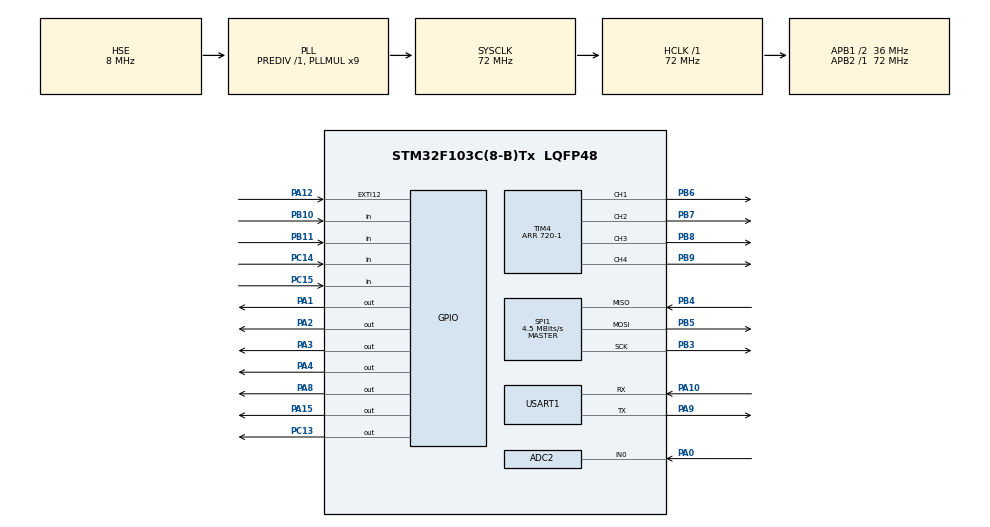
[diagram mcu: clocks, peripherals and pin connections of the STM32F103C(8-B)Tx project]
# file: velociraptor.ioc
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ADC2.Channel-4\#ChannelRegularConversion=ADC_CHANNEL_0
ADC2.NbrOfConversionFlag=1
ADC2.Rank-4\#ChannelRegularConversion=1
ADC2.SamplingTime-4\#ChannelRegularConversion=ADC_SAMPLETIME_1CYCLE_5
Dma.Request0=USART1_RX
Dma.Request1=USART1_TX
Dma.USART1_RX.0.Direction=DMA_PERIPH_TO_MEMORY
Dma.USART1_RX.0.Instance=DMA1_Channel5
Dma.USART1_RX.0.MemDataAlignment=DMA_MDATAALIGN_BYTE
Dma.USART1_RX.0.MemInc=DMA_MINC_ENABLE
Dma.USART1_RX.0.Mode=DMA_NORMAL
Dma.USART1_RX.0.PeriphDataAlignment=DMA_PDATAALIGN_BYTE
Dma.USART1_RX.0.PeriphInc=DMA_PINC_DISABLE
Dma.USART1_RX.0.Priority=DMA_PRIORITY_LOW
Dma.USART1_TX.1.Direction=DMA_MEMORY_TO_PERIPH
Dma.USART1_TX.1.Instance=DMA1_Channel4
Dma.USART1_TX.1.MemDataAlignment=DMA_MDATAALIGN_BYTE
Dma.USART1_TX.1.MemInc=DMA_MINC_ENABLE
Dma.USART1_TX.1.Mode=DMA_NORMAL
Dma.USART1_TX.1.PeriphDataAlignment=DMA_PDATAALIGN_BYTE
Dma.USART1_TX.1.PeriphInc=DMA_PINC_DISABLE
Dma.USART1_TX.1.Priority=DMA_PRIORITY_LOW
Mcu.Family=STM32F1
Mcu.Name=STM32F103C(8-B)Tx
Mcu.Package=LQFP48
NVIC.DMA1_Channel4_IRQn=true\:0\:0\:false\:false\:true\:false\:true\:true
NVIC.DMA1_Channel5_IRQn=true\:0\:0\:false\:false\:true\:false\:true\:true
NVIC.EXTI15_10_IRQn=true\:0\:0\:false\:false\:true\:true\:true\:true
NVIC.PriorityGroup=NVIC_PRIORITYGROUP_4
NVIC.TIM2_IRQn=true\:0\:0\:false\:false\:true\:true\:true\:true
NVIC.USART1_IRQn=true\:0\:0\:false\:false\:true\:true\:true\:true
PA0-WKUP.Signal=ADCx_IN0
PA1.Signal=GPIO_Output
PA10.Mode=Asynchronous
PA10.Signal=USART1_RX
PA12.GPIO_ModeDefaultEXTI=GPIO_MODE_IT_RISING
PA12.Signal=GPXTI12
PA13.Mode=Serial_Wire
PA13.Signal=SYS_JTMS-SWDIO
PA14.Mode=Serial_Wire
PA14.Signal=SYS_JTCK-SWCLK
PA15.GPIO_Speed=GPIO_SPEED_FREQ_HIGH
PA15.Signal=GPIO_Output
PA2.Signal=GPIO_Output
PA3.Signal=GPIO_Output
PA4.Signal=GPIO_Output
PA8.Signal=GPIO_Output
PA9.Mode=Asynchronous
PA9.Signal=USART1_TX
PB10.GPIO_PuPd=GPIO_PULLUP
PB10.Signal=GPIO_Input
PB11.GPIO_PuPd=GPIO_PULLUP
PB11.Signal=GPIO_Input
PB3.Mode=Full_Duplex_Master
PB3.Signal=SPI1_SCK
PB4.Mode=Full_Duplex_Master
PB4.Signal=SPI1_MISO
PB5.Mode=Full_Duplex_Master
PB5.Signal=SPI1_MOSI
PB6.Signal=S_TIM4_CH1
PB7.Signal=S_TIM4_CH2
PB8.Signal=S_TIM4_CH3
PB9.Signal=S_TIM4_CH4
PC13-TAMPER-RTC.Signal=GPIO_Output
PC14-OSC32_IN.GPIO_PuPd=GPIO_PULLUP
PC14-OSC32_IN.Signal=GPIO_Input
PC15-OSC32_OUT.GPIO_PuPd=GPIO_PULLUP
PC15-OSC32_OUT.Signal=GPIO_Input
PD0-OSC_IN.Mode=HSE-External-Oscillator
PD0-OSC_IN.Signal=RCC_OSC_IN
PD1-OSC_OUT.Mode=HSE-External-Oscillator
PD1-OSC_OUT.Signal=RCC_OSC_OUT
ProjectManager.HeapSize=0x200
ProjectManager.StackSize=0x400
ProjectManager.TargetToolchain=STM32CubeIDE
RCC.ADCPresc=RCC_ADCPCLK2_DIV6
RCC.AHBFreq_Value=72000000
RCC.APB1CLKDivider=RCC_HCLK_DIV2
RCC.APB1Freq_Value=36000000
RCC.APB1TimFreq_Value=72000000
RCC.APB2Freq_Value=72000000
RCC.APB2TimFreq_Value=72000000
RCC.HCLKFreq_Value=72000000
RCC.PLLMUL=RCC_PLL_MUL9
RCC.PLLSourceVirtual=RCC_PLLSOURCE_HSE
RCC.SYSCLKFreq_VALUE=72000000
RCC.SYSCLKSource=RCC_SYSCLKSOURCE_PLLCLK
RCC.USBFreq_Value=72000000
SH.ADCx_IN0.0=ADC2_IN0,IN0
SH.S_TIM4_CH1.0=TIM4_CH1,PWM Generation1 CH1
SH.S_TIM4_CH2.0=TIM4_CH2,PWM Generation2 CH2
SH.S_TIM4_CH3.0=TIM4_CH3,PWM Generation3 CH3
SH.S_TIM4_CH4.0=TIM4_CH4,PWM Generation4 CH4
SPI1.BaudRatePrescaler=SPI_BAUDRATEPRESCALER_16
SPI1.CLKPhase=SPI_PHASE_2EDGE
SPI1.CLKPolarity=SPI_POLARITY_HIGH
SPI1.CalculateBaudRate=4.5 MBits/s
SPI1.Direction=SPI_DIRECTION_2LINES
SPI1.Mode=SPI_MODE_MASTER
SPI1.VirtualType=VM_MASTER
TIM2.AutoReloadPreload=TIM_AUTORELOAD_PRELOAD_ENABLE
TIM2.Period=10-1
TIM2.Prescaler=720-1
TIM3.Period=1080-1
TIM3.TIM_MasterOutputTrigger=TIM_TRGO_UPDATE
TIM4.AutoReloadPreload=TIM_AUTORELOAD_PRELOAD_ENABLE
TIM4.Channel-PWM\ Generation1\ CH1=TIM_CHANNEL_1
TIM4.Channel-PWM\ Generation2\ CH2=TIM_CHANNEL_2
TIM4.Channel-PWM\ Generation3\ CH3=TIM_CHANNEL_3
TIM4.Channel-PWM\ Generation4\ CH4=TIM_CHANNEL_4
TIM4.ClockDivision=TIM_CLOCKDIVISION_DIV1
TIM4.Period=720-1
USART1.VirtualMode=VM_ASYNC
VP_TIM2_VS_ClockSourceINT.Mode=Internal
VP_TIM3_VS_ClockSourceINT.Mode=Internal
VP_TIM4_VS_ClockSourceINT.Mode=Internal
board=custom

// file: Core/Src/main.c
/* USER CODE BEGIN Header */
/**
  ******************************************************************************
  * @file           : main.c
  * @brief          : Main program body
  ******************************************************************************
  * @attention
  *
  * Copyright (c) 2024 STMicroelectronics.
  * All rights reserved.
  *
  * This software is licensed under terms that can be found in the LICENSE file
  * in the root directory of this software component.
  * If no LICENSE file comes with this software, it is provided AS-IS.
  *
  ******************************************************************************
  */
/* USER CODE END Header */
#include "main.h"

/* USER CODE BEGIN Includes */
#include "velociraptor3.h"
#include "velociraptor3_comms.h"
/* USER CODE END Includes */

ADC_HandleTypeDef hadc2;

SPI_HandleTypeDef hspi1;

TIM_HandleTypeDef htim2;
TIM_HandleTypeDef htim3;
TIM_HandleTypeDef htim4;

UART_HandleTypeDef huart1;
DMA_HandleTypeDef hdma_usart1_rx;
DMA_HandleTypeDef hdma_usart1_tx;

void SystemClock_Config(void);
static void MX_GPIO_Init(void);
static void MX_DMA_Init(void);
static void MX_TIM4_Init(void);
static void MX_USART1_UART_Init(void);
static void MX_TIM3_Init(void);
static void MX_ADC2_Init(void);
static void MX_TIM2_Init(void);
static void MX_SPI1_Init(void);

int main(void)
{

  /* MCU Configuration--------------------------------------------------------*/

  /* Reset of all peripherals, Initializes the Flash interface and the Systick. */
   HAL_Init();

  /* Configure the system clock */
  SystemClock_Config();

  /* Initialize all configured peripherals */
  MX_GPIO_Init();
  MX_DMA_Init();
  MX_TIM4_Init();
  MX_USART1_UART_Init();
  MX_TIM3_Init();
  MX_ADC2_Init();
  MX_TIM2_Init();
  MX_SPI1_Init();
  /* USER CODE BEGIN 2 */
  velociraptor3_init();
  //velociraptor2_comms_init();
  /* USER CODE END 2 */

  /* Infinite loop */
  /* USER CODE BEGIN WHILE */
  while (1)
  {
	velociraptor3_main_loop();
    /* USER CODE END WHILE */

  }
}

void SystemClock_Config(void)
{
  RCC_OscInitTypeDef RCC_OscInitStruct = {0};
  RCC_ClkInitTypeDef RCC_ClkInitStruct = {0};
  RCC_PeriphCLKInitTypeDef PeriphClkInit = {0};

  /** Initializes the RCC Oscillators according to the specified parameters
  * in the RCC_OscInitTypeDef structure.
  */
  RCC_OscInitStruct.OscillatorType = RCC_OSCILLATORTYPE_HSE;
  RCC_OscInitStruct.HSEState = RCC_HSE_ON;
  RCC_OscInitStruct.HSEPredivValue = RCC_HSE_PREDIV_DIV1;
  RCC_OscInitStruct.HSIState = RCC_HSI_ON;
  RCC_OscInitStruct.PLL.PLLState = RCC_PLL_ON;
  RCC_OscInitStruct.PLL.PLLSource = RCC_PLLSOURCE_HSE;
  RCC_OscInitStruct.PLL.PLLMUL = RCC_PLL_MUL9;
  if (HAL_RCC_OscConfig(&RCC_OscInitStruct) != HAL_OK)
  {
    Error_Handler();
  }

  /** Initializes the CPU, AHB and APB buses clocks
  */
  RCC_ClkInitStruct.ClockType = RCC_CLOCKTYPE_HCLK|RCC_CLOCKTYPE_SYSCLK
                              |RCC_CLOCKTYPE_PCLK1|RCC_CLOCKTYPE_PCLK2;
  RCC_ClkInitStruct.SYSCLKSource = RCC_SYSCLKSOURCE_PLLCLK;
  RCC_ClkInitStruct.AHBCLKDivider = RCC_SYSCLK_DIV1;
  RCC_ClkInitStruct.APB1CLKDivider = RCC_HCLK_DIV2;
  RCC_ClkInitStruct.APB2CLKDivider = RCC_HCLK_DIV1;

  if (HAL_RCC_ClockConfig(&RCC_ClkInitStruct, FLASH_LATENCY_2) != HAL_OK)
  {
    Error_Handler();
  }
  PeriphClkInit.PeriphClockSelection = RCC_PERIPHCLK_ADC;
  PeriphClkInit.AdcClockSelection = RCC_ADCPCLK2_DIV6;
  if (HAL_RCCEx_PeriphCLKConfig(&PeriphClkInit) != HAL_OK)
  {
    Error_Handler();
  }
}

static void MX_ADC2_Init(void)
{

  ADC_ChannelConfTypeDef sConfig = {0};

  /** Common config
  */
  hadc2.Instance = ADC2;
  hadc2.Init.ScanConvMode = ADC_SCAN_DISABLE;
  hadc2.Init.ContinuousConvMode = DISABLE;
  hadc2.Init.DiscontinuousConvMode = DISABLE;
  hadc2.Init.ExternalTrigConv = ADC_SOFTWARE_START;
  hadc2.Init.DataAlign = ADC_DATAALIGN_RIGHT;
  hadc2.Init.NbrOfConversion = 1;
  if (HAL_ADC_Init(&hadc2) != HAL_OK)
  {
    Error_Handler();
  }

  /** Configure Regular Channel
  */
  sConfig.Channel = ADC_CHANNEL_0;
  sConfig.Rank = ADC_REGULAR_RANK_1;
  sConfig.SamplingTime = ADC_SAMPLETIME_1CYCLE_5;
  if (HAL_ADC_ConfigChannel(&hadc2, &sConfig) != HAL_OK)
  {
    Error_Handler();
  }

}

static void MX_SPI1_Init(void)
{

  /* SPI1 parameter configuration*/
  hspi1.Instance = SPI1;
  hspi1.Init.Mode = SPI_MODE_MASTER;
  hspi1.Init.Direction = SPI_DIRECTION_2LINES;
  hspi1.Init.DataSize = SPI_DATASIZE_8BIT;
  hspi1.Init.CLKPolarity = SPI_POLARITY_HIGH;
  hspi1.Init.CLKPhase = SPI_PHASE_2EDGE;
  hspi1.Init.NSS = SPI_NSS_SOFT;
  hspi1.Init.BaudRatePrescaler = SPI_BAUDRATEPRESCALER_16;
  hspi1.Init.FirstBit = SPI_FIRSTBIT_MSB;
  hspi1.Init.TIMode = SPI_TIMODE_DISABLE;
  hspi1.Init.CRCCalculation = SPI_CRCCALCULATION_DISABLE;
  hspi1.Init.CRCPolynomial = 10;
  if (HAL_SPI_Init(&hspi1) != HAL_OK)
  {
    Error_Handler();
  }

}

static void MX_TIM2_Init(void)
{

  TIM_ClockConfigTypeDef sClockSourceConfig = {0};
  TIM_MasterConfigTypeDef sMasterConfig = {0};

  htim2.Instance = TIM2;
  htim2.Init.Prescaler = 720-1;
  htim2.Init.CounterMode = TIM_COUNTERMODE_UP;
  htim2.Init.Period = 10-1;
  htim2.Init.ClockDivision = TIM_CLOCKDIVISION_DIV1;
  htim2.Init.AutoReloadPreload = TIM_AUTORELOAD_PRELOAD_ENABLE;
  if (HAL_TIM_Base_Init(&htim2) != HAL_OK)
  {
    Error_Handler();
  }
  sClockSourceConfig.ClockSource = TIM_CLOCKSOURCE_INTERNAL;
  if (HAL_TIM_ConfigClockSource(&htim2, &sClockSourceConfig) != HAL_OK)
  {
    Error_Handler();
  }
  sMasterConfig.MasterOutputTrigger = TIM_TRGO_RESET;
  sMasterConfig.MasterSlaveMode = TIM_MASTERSLAVEMODE_DISABLE;
  if (HAL_TIMEx_MasterConfigSynchronization(&htim2, &sMasterConfig) != HAL_OK)
  {
    Error_Handler();
  }

}

static void MX_TIM3_Init(void)
{

  TIM_ClockConfigTypeDef sClockSourceConfig = {0};
  TIM_MasterConfigTypeDef sMasterConfig = {0};

  htim3.Instance = TIM3;
  htim3.Init.Prescaler = 0;
  htim3.Init.CounterMode = TIM_COUNTERMODE_UP;
  htim3.Init.Period = 1080-1;
  htim3.Init.ClockDivision = TIM_CLOCKDIVISION_DIV1;
  htim3.Init.AutoReloadPreload = TIM_AUTORELOAD_PRELOAD_DISABLE;
  if (HAL_TIM_Base_Init(&htim3) != HAL_OK)
  {
    Error_Handler();
  }
  sClockSourceConfig.ClockSource = TIM_CLOCKSOURCE_INTERNAL;
  if (HAL_TIM_ConfigClockSource(&htim3, &sClockSourceConfig) != HAL_OK)
  {
    Error_Handler();
  }
  sMasterConfig.MasterOutputTrigger = TIM_TRGO_UPDATE;
  sMasterConfig.MasterSlaveMode = TIM_MASTERSLAVEMODE_DISABLE;
  if (HAL_TIMEx_MasterConfigSynchronization(&htim3, &sMasterConfig) != HAL_OK)
  {
    Error_Handler();
  }

}

static void MX_TIM4_Init(void)
{

  TIM_ClockConfigTypeDef sClockSourceConfig = {0};
  TIM_MasterConfigTypeDef sMasterConfig = {0};
  TIM_OC_InitTypeDef sConfigOC = {0};

  htim4.Instance = TIM4;
  htim4.Init.Prescaler = 0;
  htim4.Init.CounterMode = TIM_COUNTERMODE_UP;
  htim4.Init.Period = 720-1;
  htim4.Init.ClockDivision = TIM_CLOCKDIVISION_DIV1;
  htim4.Init.AutoReloadPreload = TIM_AUTORELOAD_PRELOAD_ENABLE;
  if (HAL_TIM_Base_Init(&htim4) != HAL_OK)
  {
    Error_Handler();
  }
  sClockSourceConfig.ClockSource = TIM_CLOCKSOURCE_INTERNAL;
  if (HAL_TIM_ConfigClockSource(&htim4, &sClockSourceConfig) != HAL_OK)
  {
    Error_Handler();
  }
  if (HAL_TIM_PWM_Init(&htim4) != HAL_OK)
  {
    Error_Handler();
  }
  sMasterConfig.MasterOutputTrigger = TIM_TRGO_RESET;
  sMasterConfig.MasterSlaveMode = TIM_MASTERSLAVEMODE_DISABLE;
  if (HAL_TIMEx_MasterConfigSynchronization(&htim4, &sMasterConfig) != HAL_OK)
  {
    Error_Handler();
  }
  sConfigOC.OCMode = TIM_OCMODE_PWM1;
  sConfigOC.Pulse = 0;
  sConfigOC.OCPolarity = TIM_OCPOLARITY_HIGH;
  sConfigOC.OCFastMode = TIM_OCFAST_DISABLE;
  if (HAL_TIM_PWM_ConfigChannel(&htim4, &sConfigOC, TIM_CHANNEL_1) != HAL_OK)
  {
    Error_Handler();
  }
  if (HAL_TIM_PWM_ConfigChannel(&htim4, &sConfigOC, TIM_CHANNEL_2) != HAL_OK)
  {
    Error_Handler();
  }
  if (HAL_TIM_PWM_ConfigChannel(&htim4, &sConfigOC, TIM_CHANNEL_3) != HAL_OK)
  {
    Error_Handler();
  }
  if (HAL_TIM_PWM_ConfigChannel(&htim4, &sConfigOC, TIM_CHANNEL_4) != HAL_OK)
  {
    Error_Handler();
  }
  HAL_TIM_MspPostInit(&htim4);

}

static void MX_USART1_UART_Init(void)
{

  huart1.Instance = USART1;
  huart1.Init.BaudRate = 115200;
  huart1.Init.WordLength = UART_WORDLENGTH_8B;
  huart1.Init.StopBits = UART_STOPBITS_1;
  huart1.Init.Parity = UART_PARITY_NONE;
  huart1.Init.Mode = UART_MODE_TX_RX;
  huart1.Init.HwFlowCtl = UART_HWCONTROL_NONE;
  huart1.Init.OverSampling = UART_OVERSAMPLING_16;
  if (HAL_UART_Init(&huart1) != HAL_OK)
  {
    Error_Handler();
  }

}

static void MX_DMA_Init(void)
{

  /* DMA controller clock enable */
  __HAL_RCC_DMA1_CLK_ENABLE();

  /* DMA interrupt init */
  /* DMA1_Channel4_IRQn interrupt configuration */
  HAL_NVIC_SetPriority(DMA1_Channel4_IRQn, 0, 0);
  HAL_NVIC_EnableIRQ(DMA1_Channel4_IRQn);
  /* DMA1_Channel5_IRQn interrupt configuration */
  HAL_NVIC_SetPriority(DMA1_Channel5_IRQn, 0, 0);
  HAL_NVIC_EnableIRQ(DMA1_Channel5_IRQn);

}

static void MX_GPIO_Init(void)
{
  GPIO_InitTypeDef GPIO_InitStruct = {0};

  /* GPIO Ports Clock Enable */
  __HAL_RCC_GPIOC_CLK_ENABLE();
  __HAL_RCC_GPIOD_CLK_ENABLE();
  __HAL_RCC_GPIOA_CLK_ENABLE();
  __HAL_RCC_GPIOB_CLK_ENABLE();

  /*Configure GPIO pin Output Level */
  HAL_GPIO_WritePin(GPIOC, GPIO_PIN_13, GPIO_PIN_RESET);

  /*Configure GPIO pin Output Level */
  HAL_GPIO_WritePin(GPIOA, GPIO_PIN_1|GPIO_PIN_2|GPIO_PIN_3|GPIO_PIN_4
                          |GPIO_PIN_8|GPIO_PIN_15, GPIO_PIN_RESET);

  /*Configure GPIO pin : PC13 */
  GPIO_InitStruct.Pin = GPIO_PIN_13;
  GPIO_InitStruct.Mode = GPIO_MODE_OUTPUT_PP;
  GPIO_InitStruct.Pull = GPIO_NOPULL;
  GPIO_InitStruct.Speed = GPIO_SPEED_FREQ_LOW;
  HAL_GPIO_Init(GPIOC, &GPIO_InitStruct);

  /*Configure GPIO pins : PC14 PC15 */
  GPIO_InitStruct.Pin = GPIO_PIN_14|GPIO_PIN_15;
  GPIO_InitStruct.Mode = GPIO_MODE_INPUT;
  GPIO_InitStruct.Pull = GPIO_PULLUP;
  HAL_GPIO_Init(GPIOC, &GPIO_InitStruct);

  /*Configure GPIO pins : PA1 PA2 PA3 PA4
                           PA8 */
  GPIO_InitStruct.Pin = GPIO_PIN_1|GPIO_PIN_2|GPIO_PIN_3|GPIO_PIN_4
                          |GPIO_PIN_8;
  GPIO_InitStruct.Mode = GPIO_MODE_OUTPUT_PP;
  GPIO_InitStruct.Pull = GPIO_NOPULL;
  GPIO_InitStruct.Speed = GPIO_SPEED_FREQ_LOW;
  HAL_GPIO_Init(GPIOA, &GPIO_InitStruct);

  /*Configure GPIO pins : PB10 PB11 */
  GPIO_InitStruct.Pin = GPIO_PIN_10|GPIO_PIN_11;
  GPIO_InitStruct.Mode = GPIO_MODE_INPUT;
  GPIO_InitStruct.Pull = GPIO_PULLUP;
  HAL_GPIO_Init(GPIOB, &GPIO_InitStruct);

  /*Configure GPIO pin : PA12 */
  GPIO_InitStruct.Pin = GPIO_PIN_12;
  GPIO_InitStruct.Mode = GPIO_MODE_IT_RISING;
  GPIO_InitStruct.Pull = GPIO_NOPULL;
  HAL_GPIO_Init(GPIOA, &GPIO_InitStruct);

  /*Configure GPIO pin : PA15 */
  GPIO_InitStruct.Pin = GPIO_PIN_15;
  GPIO_InitStruct.Mode = GPIO_MODE_OUTPUT_PP;
  GPIO_InitStruct.Pull = GPIO_NOPULL;
  GPIO_InitStruct.Speed = GPIO_SPEED_FREQ_HIGH;
  HAL_GPIO_Init(GPIOA, &GPIO_InitStruct);

  /* EXTI interrupt init*/
  HAL_NVIC_SetPriority(EXTI15_10_IRQn, 0, 0);
  HAL_NVIC_EnableIRQ(EXTI15_10_IRQn);

}

void Error_Handler(void)
{
  __disable_irq();
  while (1)
  {
  }
}
